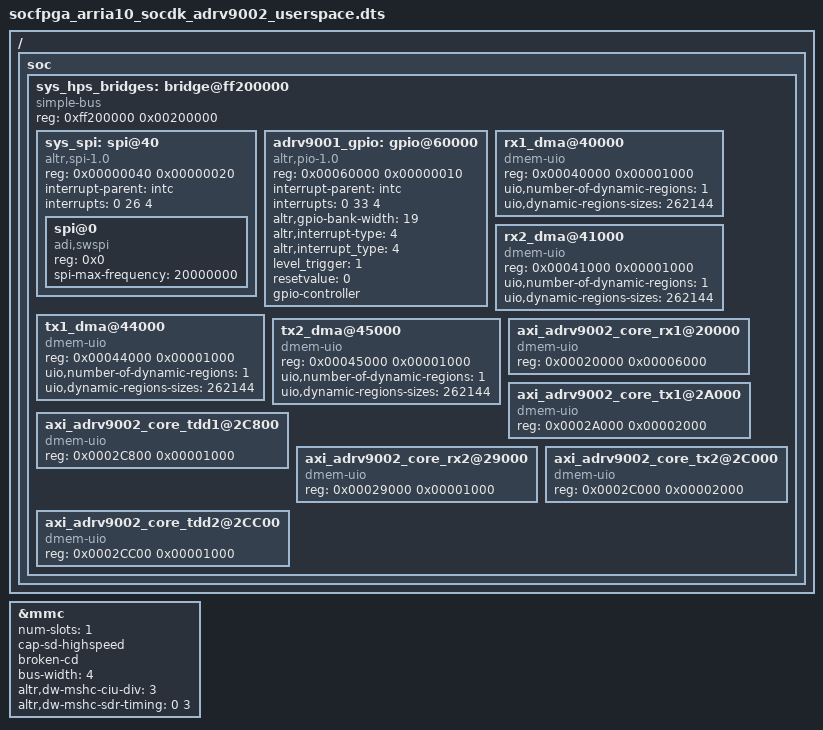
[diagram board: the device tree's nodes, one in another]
// SPDX-License-Identifier: GPL-2.0
/*
 * Analog Devices ADRV9002
 *
 * hdl_project: <adrv9001/a10soc>
 * board_revision: <>
 *
 * Copyright (C) 2024 Analog Devices Inc.
 */
/dts-v1/;
#include "socfpga_arria10_socdk.dtsi"
#include <dt-bindings/gpio/gpio.h>

&mmc {
	status = "okay";
	num-slots = <1>;
	cap-sd-highspeed;
	broken-cd;
	bus-width = <4>;
	altr,dw-mshc-ciu-div = <3>;
	altr,dw-mshc-sdr-timing = <0 3>;
};

/ {
	soc {
		sys_hps_bridges: bridge@ff200000 {
			compatible = "simple-bus";
			reg = <0xff200000 0x00200000>;
			#address-cells = <1>;
			#size-cells = <1>;
			ranges = <0x00000000 0xff200000 0x00200000>;

			sys_spi: spi@40 {
				compatible = "altr,spi-1.0";
				reg = <0x00000040 0x00000020>;
				interrupt-parent = <&intc>;
				interrupts = <0 26 4>;
				#address-cells = <0x1>;
				#size-cells = <0x0>;

				spi@0 {
					compatible = "adi,swspi";
					reg = <0x0>;
					spi-max-frequency = <20000000>;
				};
			};

			adrv9001_gpio: gpio@60000 {
				compatible = "altr,pio-1.0";
				reg = <0x00060000 0x00000010>;
				interrupt-parent = <&intc>;
				interrupts = <0 33 4>;
				altr,gpio-bank-width = <19>;
				altr,interrupt-type = <4>;
				altr,interrupt_type = <4>;
				level_trigger = <1>;
				resetvalue = <0>;
				#gpio-cells = <2>;
				gpio-controller;
			};

			rx1_dma@40000 {
				compatible = "dmem-uio";
				reg = <0x00040000 0x00001000>;
				uio,number-of-dynamic-regions = <1>;
				uio,dynamic-regions-sizes = <262144>;
			};

			rx2_dma@41000 {
				compatible = "dmem-uio";
				reg = <0x00041000 0x00001000>;
				uio,number-of-dynamic-regions = <1>;
				uio,dynamic-regions-sizes = <262144>;
			};

			tx1_dma@44000 {
				compatible = "dmem-uio";
				reg = <0x00044000 0x00001000>;
				uio,number-of-dynamic-regions = <1>;
				uio,dynamic-regions-sizes = <262144>;
			};

			tx2_dma@45000 {
				compatible = "dmem-uio";
				reg = <0x00045000 0x00001000>;
				uio,number-of-dynamic-regions = <1>;
				uio,dynamic-regions-sizes = <262144>;
			};

			axi_adrv9002_core_rx1@20000 {
				compatible = "dmem-uio";
				reg = <0x00020000 0x00006000>;
			};

			axi_adrv9002_core_tx1@2A000 {
				compatible = "dmem-uio";
				reg = <0x0002A000 0x00002000>;
			};

			axi_adrv9002_core_tdd1@2C800 {
				compatible = "dmem-uio";
				reg = <0x0002C800 0x00001000>;
			};

			axi_adrv9002_core_rx2@29000 {
				compatible = "dmem-uio";
				reg = <0x00029000 0x00001000>;
			};

			axi_adrv9002_core_tx2@2C000 {
				compatible = "dmem-uio";
				reg = <0x0002C000 0x00002000>;
			};

			axi_adrv9002_core_tdd2@2CC00 {
				compatible = "dmem-uio";
				reg = <0x0002CC00 0x00001000>;
			};
		};
	};
};
